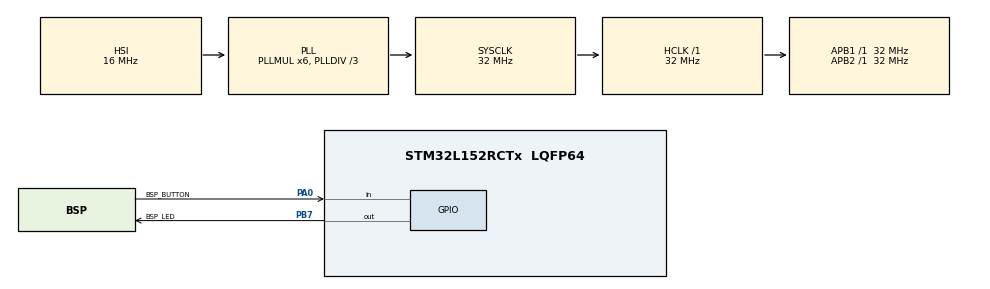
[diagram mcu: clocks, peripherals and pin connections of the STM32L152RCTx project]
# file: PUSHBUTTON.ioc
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Mcu.Family=STM32L1
Mcu.Name=STM32L152RCTx
Mcu.Package=LQFP64
NVIC.PriorityGroup=NVIC_PRIORITYGROUP_0
PA0-WKUP1.GPIO_Label=BSP_BUTTON
PA0-WKUP1.GPIO_PuPd=GPIO_NOPULL
PA0-WKUP1.Signal=GPIO_Input
PB7.GPIO_Label=BSP_LED
PB7.Signal=GPIO_Output
ProjectManager.HeapSize=0x200
ProjectManager.StackSize=0x400
ProjectManager.TargetToolchain=STM32CubeIDE
RCC.48MHZClocksFreq_Value=48000000
RCC.AHBFreq_Value=32000000
RCC.APB1Freq_Value=32000000
RCC.APB1TimFreq_Value=32000000
RCC.APB2Freq_Value=32000000
RCC.APB2TimFreq_Value=32000000
RCC.HCLKFreq_Value=32000000
RCC.HSE_VALUE=8000000
RCC.HSI_VALUE=16000000
RCC.LSE_VALUE=32768
RCC.MSI_VALUE=2097000
RCC.PLLDIV=RCC_PLL_DIV3
RCC.PLLMUL=RCC_PLL_MUL6
RCC.RTCClockSelectionVirtual=RCC_RTCCLKSOURCE_LSE
RCC.SYSCLKFreq_VALUE=32000000
RCC.SYSCLKSource=RCC_SYSCLKSOURCE_PLLCLK
RCC.USBOutput=48000000
RCC.VCOOutputFreq_Value=96000000
board=STM32L152C-DISCO

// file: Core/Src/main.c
/* USER CODE BEGIN Header */
/**
  ******************************************************************************
  * @file           : main.c
  * @brief          : Main program body
  ******************************************************************************
  * @attention
  *
  * Copyright (c) 2023 STMicroelectronics.
  * All rights reserved.
  *
  * This software is licensed under terms that can be found in the LICENSE file
  * in the root directory of this software component.
  * If no LICENSE file comes with this software, it is provided AS-IS.
  *
  ******************************************************************************
  */
/* USER CODE END Header */
#include "main.h"

void SystemClock_Config(void);
static void MX_GPIO_Init(void);

int main(void)
{

  /* MCU Configuration--------------------------------------------------------*/

  /* Reset of all peripherals, Initializes the Flash interface and the Systick. */
  HAL_Init();

  /* Configure the system clock */
  SystemClock_Config();

  /* Initialize all configured peripherals */
  MX_GPIO_Init();
  /* USER CODE BEGIN 2 */
  uint8_t Button_val=0;

  /* USER CODE END 2 */

  /* Infinite loop */
  while (1)
  {

    /* USER CODE BEGIN 3 */

	  Button_val=HAL_GPIO_ReadPin(BSP_BUTTON_GPIO_Port, BSP_BUTTON_Pin);
	 	  if(Button_val==0){
	 		  HAL_GPIO_WritePin(BSP_LED_GPIO_Port,BSP_LED_Pin,GPIO_PIN_RESET);
	 	  }else{
	 		  HAL_GPIO_WritePin(BSP_LED_GPIO_Port,BSP_LED_Pin,GPIO_PIN_SET);

	 	  }
  }
  /* USER CODE END 3 */
}

void SystemClock_Config(void)
{
  RCC_OscInitTypeDef RCC_OscInitStruct = {0};
  RCC_ClkInitTypeDef RCC_ClkInitStruct = {0};

  /** Configure the main internal regulator output voltage
  */
  __HAL_PWR_VOLTAGESCALING_CONFIG(PWR_REGULATOR_VOLTAGE_SCALE1);

  /** Initializes the RCC Oscillators according to the specified parameters
  * in the RCC_OscInitTypeDef structure.
  */
  RCC_OscInitStruct.OscillatorType = RCC_OSCILLATORTYPE_HSI;
  RCC_OscInitStruct.HSIState = RCC_HSI_ON;
  RCC_OscInitStruct.HSICalibrationValue = RCC_HSICALIBRATION_DEFAULT;
  RCC_OscInitStruct.PLL.PLLState = RCC_PLL_ON;
  RCC_OscInitStruct.PLL.PLLSource = RCC_PLLSOURCE_HSI;
  RCC_OscInitStruct.PLL.PLLMUL = RCC_PLL_MUL6;
  RCC_OscInitStruct.PLL.PLLDIV = RCC_PLL_DIV3;
  if (HAL_RCC_OscConfig(&RCC_OscInitStruct) != HAL_OK)
  {
    Error_Handler();
  }

  /** Initializes the CPU, AHB and APB buses clocks
  */
  RCC_ClkInitStruct.ClockType = RCC_CLOCKTYPE_HCLK|RCC_CLOCKTYPE_SYSCLK
                              |RCC_CLOCKTYPE_PCLK1|RCC_CLOCKTYPE_PCLK2;
  RCC_ClkInitStruct.SYSCLKSource = RCC_SYSCLKSOURCE_PLLCLK;
  RCC_ClkInitStruct.AHBCLKDivider = RCC_SYSCLK_DIV1;
  RCC_ClkInitStruct.APB1CLKDivider = RCC_HCLK_DIV1;
  RCC_ClkInitStruct.APB2CLKDivider = RCC_HCLK_DIV1;

  if (HAL_RCC_ClockConfig(&RCC_ClkInitStruct, FLASH_LATENCY_1) != HAL_OK)
  {
    Error_Handler();
  }
}

static void MX_GPIO_Init(void)
{
  GPIO_InitTypeDef GPIO_InitStruct = {0};

  /* GPIO Ports Clock Enable */
  __HAL_RCC_GPIOA_CLK_ENABLE();
  __HAL_RCC_GPIOB_CLK_ENABLE();

  /*Configure GPIO pin Output Level */
  HAL_GPIO_WritePin(BSP_LED_GPIO_Port, BSP_LED_Pin, GPIO_PIN_RESET);

  /*Configure GPIO pin : BSP_BUTTON_Pin */
  GPIO_InitStruct.Pin = BSP_BUTTON_Pin;
  GPIO_InitStruct.Mode = GPIO_MODE_INPUT;
  GPIO_InitStruct.Pull = GPIO_NOPULL;
  HAL_GPIO_Init(BSP_BUTTON_GPIO_Port, &GPIO_InitStruct);

  /*Configure GPIO pin : BSP_LED_Pin */
  GPIO_InitStruct.Pin = BSP_LED_Pin;
  GPIO_InitStruct.Mode = GPIO_MODE_OUTPUT_PP;
  GPIO_InitStruct.Pull = GPIO_NOPULL;
  GPIO_InitStruct.Speed = GPIO_SPEED_FREQ_LOW;
  HAL_GPIO_Init(BSP_LED_GPIO_Port, &GPIO_InitStruct);

}

void Error_Handler(void)
{
  __disable_irq();
  while (1)
  {
  }
}
